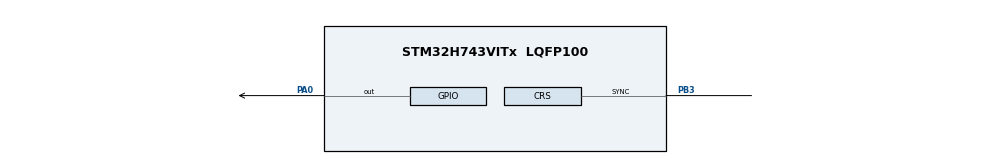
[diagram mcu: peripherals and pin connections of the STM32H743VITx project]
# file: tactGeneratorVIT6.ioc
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Mcu.Family=STM32H7
Mcu.Name=STM32H743VITx
Mcu.Package=LQFP100
NVIC.PriorityGroup=NVIC_PRIORITYGROUP_4
PA0.Signal=GPIO_Output
PB3\ (JTDO/TRACESWO).Mode=CRS SYNC Source GPIO
PB3\ (JTDO/TRACESWO).Signal=CRS_SYNC
PH0-OSC_IN\ (PH0).Mode=HSE-External-Oscillator
PH0-OSC_IN\ (PH0).Signal=RCC_OSC_IN
PH1-OSC_OUT\ (PH1).Mode=HSE-External-Oscillator
PH1-OSC_OUT\ (PH1).Signal=RCC_OSC_OUT
ProjectManager.HeapSize=0x200
ProjectManager.StackSize=0x400
ProjectManager.TargetToolchain=STM32CubeIDE
RCC.ADCFreq_Value=129000000
RCC.APB1Freq_Value=100000000
RCC.APB2Freq_Value=100000000
RCC.APB3Freq_Value=100000000
RCC.APB4Freq_Value=100000000
RCC.CortexFreq_Value=100000000
RCC.DIVN1=100
RCC.HCLKFreq_Value=100000000
RCC.SYSCLKFreq_VALUE=100000000
RCC.SYSCLKSource=RCC_SYSCLKSOURCE_PLLCLK
RCC.USBFreq_Value=100000000
board=custom

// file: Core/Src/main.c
/* USER CODE BEGIN Header */
/**
  ******************************************************************************
  * @file           : main.c
  * @brief          : Main program body
  ******************************************************************************
  * @attention
  *
  * <h2><center>&copy; Copyright (c) 2020 STMicroelectronics.
  * All rights reserved.</center></h2>
  *
  * This software component is licensed by ST under BSD 3-Clause license,
  * the "License"; You may not use this file except in compliance with the
  * License. You may obtain a copy of the License at:
  *                        opensource.org/licenses/BSD-3-Clause
  *
  ******************************************************************************
  */
/* USER CODE END Header */

#include "main.h"

void SystemClock_Config(void);
static void MX_GPIO_Init(void);

int main(void)
{

  /* MCU Configuration--------------------------------------------------------*/

  /* Reset of all peripherals, Initializes the Flash interface and the Systick. */
  HAL_Init();

  /* Configure the system clock */
  SystemClock_Config();

  /* Initialize all configured peripherals */
  MX_GPIO_Init();

  /* Infinite loop */
  /* USER CODE BEGIN WHILE */
  while (1)
  {
	  HAL_GPIO_TogglePin(GPIOA, GPIO_PIN_0);
    /* USER CODE END WHILE */

  }
}

void SystemClock_Config(void)
{
  RCC_OscInitTypeDef RCC_OscInitStruct = {0};
  RCC_ClkInitTypeDef RCC_ClkInitStruct = {0};
  RCC_CRSInitTypeDef RCC_CRSInitStruct = {0};

  /** Supply configuration update enable
  */
  HAL_PWREx_ConfigSupply(PWR_LDO_SUPPLY);
  /** Configure the main internal regulator output voltage
  */
  __HAL_PWR_VOLTAGESCALING_CONFIG(PWR_REGULATOR_VOLTAGE_SCALE3);

  while(!__HAL_PWR_GET_FLAG(PWR_FLAG_VOSRDY)) {}
  /** Initializes the CPU, AHB and APB busses clocks
  */
  RCC_OscInitStruct.OscillatorType = RCC_OSCILLATORTYPE_HSI;
  RCC_OscInitStruct.HSIState = RCC_HSI_DIV1;
  RCC_OscInitStruct.HSICalibrationValue = RCC_HSICALIBRATION_DEFAULT;
  RCC_OscInitStruct.PLL.PLLState = RCC_PLL_ON;
  RCC_OscInitStruct.PLL.PLLSource = RCC_PLLSOURCE_HSI;
  RCC_OscInitStruct.PLL.PLLM = 32;
  RCC_OscInitStruct.PLL.PLLN = 100;
  RCC_OscInitStruct.PLL.PLLP = 2;
  RCC_OscInitStruct.PLL.PLLQ = 2;
  RCC_OscInitStruct.PLL.PLLR = 2;
  RCC_OscInitStruct.PLL.PLLRGE = RCC_PLL1VCIRANGE_1;
  RCC_OscInitStruct.PLL.PLLVCOSEL = RCC_PLL1VCOWIDE;
  RCC_OscInitStruct.PLL.PLLFRACN = 0;
  if (HAL_RCC_OscConfig(&RCC_OscInitStruct) != HAL_OK)
  {
    Error_Handler();
  }
  /** Initializes the CPU, AHB and APB busses clocks
  */
  RCC_ClkInitStruct.ClockType = RCC_CLOCKTYPE_HCLK|RCC_CLOCKTYPE_SYSCLK
                              |RCC_CLOCKTYPE_PCLK1|RCC_CLOCKTYPE_PCLK2
                              |RCC_CLOCKTYPE_D3PCLK1|RCC_CLOCKTYPE_D1PCLK1;
  RCC_ClkInitStruct.SYSCLKSource = RCC_SYSCLKSOURCE_PLLCLK;
  RCC_ClkInitStruct.SYSCLKDivider = RCC_SYSCLK_DIV1;
  RCC_ClkInitStruct.AHBCLKDivider = RCC_HCLK_DIV1;
  RCC_ClkInitStruct.APB3CLKDivider = RCC_APB3_DIV1;
  RCC_ClkInitStruct.APB1CLKDivider = RCC_APB1_DIV1;
  RCC_ClkInitStruct.APB2CLKDivider = RCC_APB2_DIV1;
  RCC_ClkInitStruct.APB4CLKDivider = RCC_APB4_DIV1;

  if (HAL_RCC_ClockConfig(&RCC_ClkInitStruct, FLASH_LATENCY_1) != HAL_OK)
  {
    Error_Handler();
  }
  /** Enable the SYSCFG APB clock
  */
  __HAL_RCC_CRS_CLK_ENABLE();
  /** Configures CRS
  */
  RCC_CRSInitStruct.Prescaler = RCC_CRS_SYNC_DIV1;
  RCC_CRSInitStruct.Source = RCC_CRS_SYNC_SOURCE_PIN;
  RCC_CRSInitStruct.Polarity = RCC_CRS_SYNC_POLARITY_RISING;
  RCC_CRSInitStruct.ReloadValue = __HAL_RCC_CRS_RELOADVALUE_CALCULATE(48000000,1);
  RCC_CRSInitStruct.ErrorLimitValue = 34;
  RCC_CRSInitStruct.HSI48CalibrationValue = 32;

  HAL_RCCEx_CRSConfig(&RCC_CRSInitStruct);
}

static void MX_GPIO_Init(void)
{
  GPIO_InitTypeDef GPIO_InitStruct = {0};

  /* GPIO Ports Clock Enable */
  __HAL_RCC_GPIOH_CLK_ENABLE();
  __HAL_RCC_GPIOA_CLK_ENABLE();
  __HAL_RCC_GPIOB_CLK_ENABLE();

  /*Configure GPIO pin Output Level */
  HAL_GPIO_WritePin(GPIOA, GPIO_PIN_0, GPIO_PIN_RESET);

  /*Configure GPIO pin : PA0 */
  GPIO_InitStruct.Pin = GPIO_PIN_0;
  GPIO_InitStruct.Mode = GPIO_MODE_OUTPUT_PP;
  GPIO_InitStruct.Pull = GPIO_NOPULL;
  GPIO_InitStruct.Speed = GPIO_SPEED_FREQ_LOW;
  HAL_GPIO_Init(GPIOA, &GPIO_InitStruct);

  /*Configure GPIO pin : PB3 */
  GPIO_InitStruct.Pin = GPIO_PIN_3;
  GPIO_InitStruct.Mode = GPIO_MODE_AF_PP;
  GPIO_InitStruct.Pull = GPIO_NOPULL;
  GPIO_InitStruct.Speed = GPIO_SPEED_FREQ_LOW;
  GPIO_InitStruct.Alternate = GPIO_AF10_CRS_SYNC;
  HAL_GPIO_Init(GPIOB, &GPIO_InitStruct);

}

void Error_Handler(void)
{
}

/************************ (C) COPYRIGHT STMicroelectronics *****END OF FILE****/
